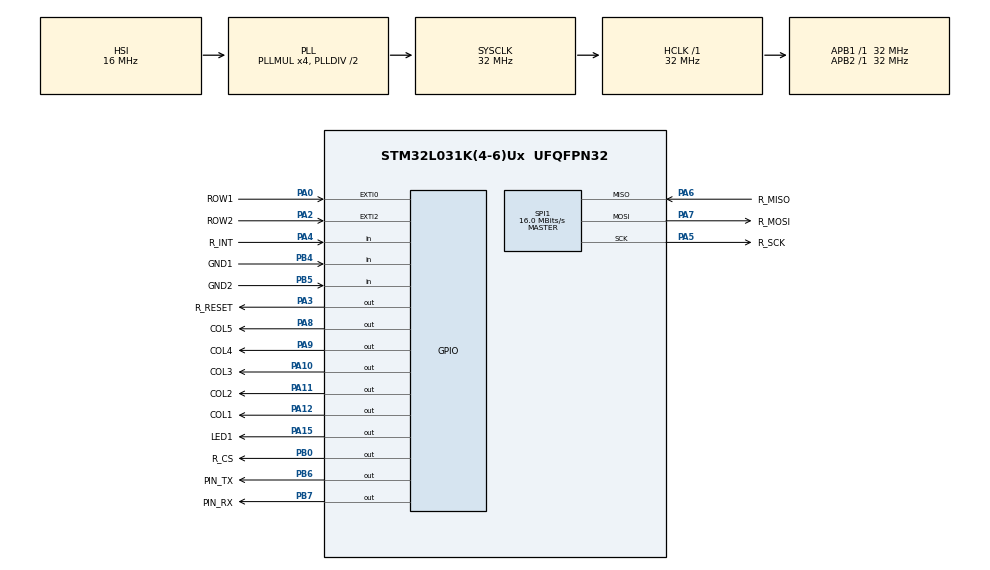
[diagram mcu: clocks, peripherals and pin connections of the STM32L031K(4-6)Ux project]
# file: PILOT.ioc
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Mcu.Family=STM32L0
Mcu.Name=STM32L031K(4-6)Ux
Mcu.Package=UFQFPN32
PA0-CK_IN.GPIO_Label=ROW1
PA0-CK_IN.GPIO_ModeDefaultEXTI=GPIO_MODE_EVT_FALLING
PA0-CK_IN.GPIO_PuPd=GPIO_PULLUP
PA0-CK_IN.Signal=GPXTI0
PA10.GPIO_Label=COL3
PA10.GPIO_ModeDefaultOutputPP=GPIO_MODE_OUTPUT_OD
PA10.Signal=GPIO_Output
PA11.GPIO_Label=COL2
PA11.GPIO_ModeDefaultOutputPP=GPIO_MODE_OUTPUT_OD
PA11.Signal=GPIO_Output
PA12.GPIO_Label=COL1
PA12.GPIO_ModeDefaultOutputPP=GPIO_MODE_OUTPUT_OD
PA12.Signal=GPIO_Output
PA13.Mode=Serial_Wire
PA13.Signal=SYS_SWDIO
PA14.Mode=Serial_Wire
PA14.Signal=SYS_SWCLK
PA15.GPIO_Label=LED1
PA15.Signal=GPIO_Output
PA2.GPIO_Label=ROW2
PA2.GPIO_ModeDefaultEXTI=GPIO_MODE_EVT_FALLING
PA2.GPIO_PuPd=GPIO_PULLUP
PA2.Signal=GPXTI2
PA3.GPIO_Label=R_RESET
PA3.Signal=GPIO_Output
PA4.GPIO_Label=R_INT
PA4.Signal=GPIO_Input
PA5.GPIO_Label=R_SCK
PA5.Mode=Full_Duplex_Master
PA5.Signal=SPI1_SCK
PA6.GPIO_Label=R_MISO
PA6.Mode=Full_Duplex_Master
PA6.Signal=SPI1_MISO
PA7.GPIO_Label=R_MOSI
PA7.Mode=Full_Duplex_Master
PA7.Signal=SPI1_MOSI
PA8.GPIO_Label=COL5
PA8.GPIO_ModeDefaultOutputPP=GPIO_MODE_OUTPUT_OD
PA8.Signal=GPIO_Output
PA9.GPIO_Label=COL4
PA9.GPIO_ModeDefaultOutputPP=GPIO_MODE_OUTPUT_OD
PA9.Signal=GPIO_Output
PB0.GPIO_Label=R_CS
PB0.Signal=GPIO_Output
PB4.GPIO_Label=GND1
PB4.Signal=GPIO_Input
PB5.GPIO_Label=GND2
PB5.Signal=GPIO_Input
PB6.GPIO_Label=PIN_TX
PB6.Signal=GPIO_Output
PB7.GPIO_Label=PIN_RX
PB7.Signal=GPIO_Output
ProjectManager.HeapSize=0x200
ProjectManager.StackSize=0x400
ProjectManager.TargetToolchain=STM32CubeIDE
RCC.AHBFreq_Value=32000000
RCC.APB1Freq_Value=32000000
RCC.APB1TimFreq_Value=32000000
RCC.APB2Freq_Value=32000000
RCC.APB2TimFreq_Value=32000000
RCC.HCLKFreq_Value=32000000
RCC.HSE_VALUE=8000000
RCC.HSI16_VALUE=16000000
RCC.HSI_VALUE=16000000
RCC.LSE_VALUE=32768
RCC.MSI_VALUE=2097000
RCC.PLLMUL=RCC_PLLMUL_4
RCC.SYSCLKFreq_VALUE=32000000
RCC.SYSCLKSource=RCC_SYSCLKSOURCE_PLLCLK
RCC.VCOOutputFreq_Value=64000000
SPI1.CalculateBaudRate=16.0 MBits/s
SPI1.Direction=SPI_DIRECTION_2LINES
SPI1.Mode=SPI_MODE_MASTER
SPI1.VirtualType=VM_MASTER
board=custom

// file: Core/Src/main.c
/* USER CODE BEGIN Header */
/**
  ******************************************************************************
  * @file           : main.c
  * @brief          : Main program body
  ******************************************************************************
  * @attention
  *
  * <h2><center>&copy; Copyright (c) 2021 STMicroelectronics.
  * All rights reserved.</center></h2>
  *
  * This software component is licensed by ST under BSD 3-Clause license,
  * the "License"; You may not use this file except in compliance with the
  * License. You may obtain a copy of the License at:
  *                        opensource.org/licenses/BSD-3-Clause
  *
  ******************************************************************************
  */
/* USER CODE END Header */
#include "main.h"

/* USER CODE BEGIN Includes */
#include "UMain.h"

/* USER CODE END Includes */

SPI_HandleTypeDef hspi1;

void SystemClock_Config(void);
static void MX_GPIO_Init(void);
static void MX_SPI1_Init(void);

int main(void)
{

  /* MCU Configuration--------------------------------------------------------*/

  /* Reset of all peripherals, Initializes the Flash interface and the Systick. */
  HAL_Init();

  /* Configure the system clock */
  SystemClock_Config();

  /* Initialize all configured peripherals */
  MX_GPIO_Init();
  MX_SPI1_Init();

  /* Infinite loop */
  /* USER CODE BEGIN WHILE */

  uMain();

  while (1)
  {
    /* USER CODE END WHILE */

  }
}

void SystemClock_Config(void)
{
  RCC_OscInitTypeDef RCC_OscInitStruct = {0};
  RCC_ClkInitTypeDef RCC_ClkInitStruct = {0};

  /** Configure the main internal regulator output voltage
  */
  __HAL_PWR_VOLTAGESCALING_CONFIG(PWR_REGULATOR_VOLTAGE_SCALE1);

  /** Initializes the RCC Oscillators according to the specified parameters
  * in the RCC_OscInitTypeDef structure.
  */
  RCC_OscInitStruct.OscillatorType = RCC_OSCILLATORTYPE_HSI;
  RCC_OscInitStruct.HSIState = RCC_HSI_ON;
  RCC_OscInitStruct.HSICalibrationValue = RCC_HSICALIBRATION_DEFAULT;
  RCC_OscInitStruct.PLL.PLLState = RCC_PLL_ON;
  RCC_OscInitStruct.PLL.PLLSource = RCC_PLLSOURCE_HSI;
  RCC_OscInitStruct.PLL.PLLMUL = RCC_PLLMUL_4;
  RCC_OscInitStruct.PLL.PLLDIV = RCC_PLLDIV_2;
  if (HAL_RCC_OscConfig(&RCC_OscInitStruct) != HAL_OK)
  {
    Error_Handler();
  }

  /** Initializes the CPU, AHB and APB buses clocks
  */
  RCC_ClkInitStruct.ClockType = RCC_CLOCKTYPE_HCLK|RCC_CLOCKTYPE_SYSCLK
                              |RCC_CLOCKTYPE_PCLK1|RCC_CLOCKTYPE_PCLK2;
  RCC_ClkInitStruct.SYSCLKSource = RCC_SYSCLKSOURCE_PLLCLK;
  RCC_ClkInitStruct.AHBCLKDivider = RCC_SYSCLK_DIV1;
  RCC_ClkInitStruct.APB1CLKDivider = RCC_HCLK_DIV1;
  RCC_ClkInitStruct.APB2CLKDivider = RCC_HCLK_DIV1;

  if (HAL_RCC_ClockConfig(&RCC_ClkInitStruct, FLASH_LATENCY_1) != HAL_OK)
  {
    Error_Handler();
  }
}

static void MX_SPI1_Init(void)
{

  /* SPI1 parameter configuration*/
  hspi1.Instance = SPI1;
  hspi1.Init.Mode = SPI_MODE_MASTER;
  hspi1.Init.Direction = SPI_DIRECTION_2LINES;
  hspi1.Init.DataSize = SPI_DATASIZE_8BIT;
  hspi1.Init.CLKPolarity = SPI_POLARITY_LOW;
  hspi1.Init.CLKPhase = SPI_PHASE_1EDGE;
  hspi1.Init.NSS = SPI_NSS_SOFT;
  hspi1.Init.BaudRatePrescaler = SPI_BAUDRATEPRESCALER_2;
  hspi1.Init.FirstBit = SPI_FIRSTBIT_MSB;
  hspi1.Init.TIMode = SPI_TIMODE_DISABLE;
  hspi1.Init.CRCCalculation = SPI_CRCCALCULATION_DISABLE;
  hspi1.Init.CRCPolynomial = 7;
  if (HAL_SPI_Init(&hspi1) != HAL_OK)
  {
    Error_Handler();
  }

}

static void MX_GPIO_Init(void)
{
  GPIO_InitTypeDef GPIO_InitStruct = {0};

  /* GPIO Ports Clock Enable */
  __HAL_RCC_GPIOA_CLK_ENABLE();
  __HAL_RCC_GPIOB_CLK_ENABLE();

  /*Configure GPIO pin Output Level */
  HAL_GPIO_WritePin(GPIOA, R_RESET_Pin|COL5_Pin|COL4_Pin|COL3_Pin
                          |COL2_Pin|COL1_Pin|LED1_Pin, GPIO_PIN_RESET);

  /*Configure GPIO pin Output Level */
  HAL_GPIO_WritePin(GPIOB, R_CS_Pin|PIN_TX_Pin|PIN_RX_Pin, GPIO_PIN_RESET);

  /*Configure GPIO pins : ROW1_Pin ROW2_Pin */
  GPIO_InitStruct.Pin = ROW1_Pin|ROW2_Pin;
  GPIO_InitStruct.Mode = GPIO_MODE_EVT_FALLING;
  GPIO_InitStruct.Pull = GPIO_PULLUP;
  HAL_GPIO_Init(GPIOA, &GPIO_InitStruct);

  /*Configure GPIO pins : R_RESET_Pin LED1_Pin */
  GPIO_InitStruct.Pin = R_RESET_Pin|LED1_Pin;
  GPIO_InitStruct.Mode = GPIO_MODE_OUTPUT_PP;
  GPIO_InitStruct.Pull = GPIO_NOPULL;
  GPIO_InitStruct.Speed = GPIO_SPEED_FREQ_LOW;
  HAL_GPIO_Init(GPIOA, &GPIO_InitStruct);

  /*Configure GPIO pin : R_INT_Pin */
  GPIO_InitStruct.Pin = R_INT_Pin;
  GPIO_InitStruct.Mode = GPIO_MODE_INPUT;
  GPIO_InitStruct.Pull = GPIO_NOPULL;
  HAL_GPIO_Init(R_INT_GPIO_Port, &GPIO_InitStruct);

  /*Configure GPIO pins : R_CS_Pin PIN_TX_Pin PIN_RX_Pin */
  GPIO_InitStruct.Pin = R_CS_Pin|PIN_TX_Pin|PIN_RX_Pin;
  GPIO_InitStruct.Mode = GPIO_MODE_OUTPUT_PP;
  GPIO_InitStruct.Pull = GPIO_NOPULL;
  GPIO_InitStruct.Speed = GPIO_SPEED_FREQ_LOW;
  HAL_GPIO_Init(GPIOB, &GPIO_InitStruct);

  /*Configure GPIO pins : COL5_Pin COL4_Pin COL3_Pin COL2_Pin
                           COL1_Pin */
  GPIO_InitStruct.Pin = COL5_Pin|COL4_Pin|COL3_Pin|COL2_Pin
                          |COL1_Pin;
  GPIO_InitStruct.Mode = GPIO_MODE_OUTPUT_OD;
  GPIO_InitStruct.Pull = GPIO_NOPULL;
  GPIO_InitStruct.Speed = GPIO_SPEED_FREQ_LOW;
  HAL_GPIO_Init(GPIOA, &GPIO_InitStruct);

  /*Configure GPIO pins : GND1_Pin GND2_Pin */
  GPIO_InitStruct.Pin = GND1_Pin|GND2_Pin;
  GPIO_InitStruct.Mode = GPIO_MODE_INPUT;
  GPIO_InitStruct.Pull = GPIO_NOPULL;
  HAL_GPIO_Init(GPIOB, &GPIO_InitStruct);

}

void Error_Handler(void)
{
}
